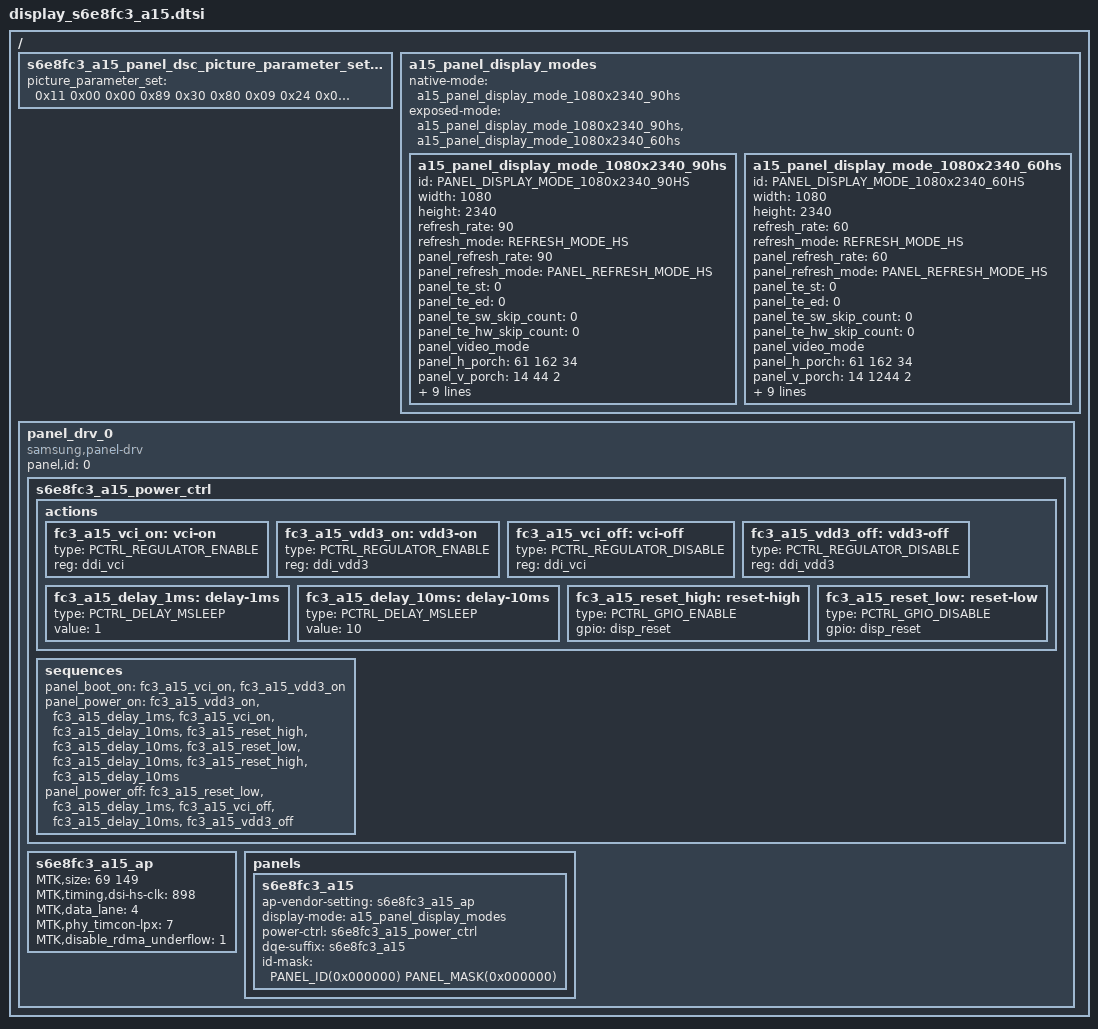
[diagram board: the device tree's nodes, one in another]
/*
 * Samsung Exynos SoC series Panel driver
 *
 * Copyright (c) 2020 Samsung Electronics Co., Ltd
 *
 * This program is free software; you can redistribute it and/or modify
 * it under the terms of the GNU General Public License version 2 as
 * published by the Free Software Foundation.
 */

#include <dt-bindings/display/panel-display.h>

/ {
	fragment@panel_display_mode {
		target-path = "/";
		__overlay__ {
			s6e8fc3_a15_panel_dsc_picture_parameter_set_default:
			s6e8fc3_a15_panel_dsc_picture_parameter_set_default {
					picture_parameter_set = /bits/ 8 <
						0x11 0x00 0x00 0x89 0x30 0x80 0x09 0x24
						0x04 0x38 0x00 0x2D 0x02 0x1C 0x02 0x1C
						0x02 0x00 0x02 0x0E 0x00 0x20 0x04 0x5A
						0x00 0x07 0x00 0x0C 0x02 0x2F 0x02 0x43
						0x18 0x00 0x10 0xF0 0x03 0x0C 0x20 0x00
						0x06 0x0B 0x0B 0x33 0x0E 0x1C 0x2A 0x38
						0x46 0x54 0x62 0x69 0x70 0x77 0x79 0x7B
						0x7D 0x7E 0x01 0x02 0x01 0x00 0x09 0x40
						0x09 0xBE 0x19 0xFC 0x19 0xFA 0x19 0xF8
						0x1A 0x38 0x1A 0x78 0x1A 0xB6 0x2A 0xF6
						0x2B 0x34 0x2B 0x74 0x3B 0x74 0x6B 0xF4
						0x00 0x00 0x00 0x00 0x00 0x00 0x00 0x00
						0x00 0x00 0x00 0x00 0x00 0x00 0x00 0x00
						0x00 0x00 0x00 0x00 0x00 0x00 0x00 0x00
						0x00 0x00 0x00 0x00 0x00 0x00 0x00 0x00
						0x00 0x00 0x00 0x00 0x00 0x00 0x00 0x00
					>;
			};

			a15_panel_display_modes:
			a15_panel_display_modes {
				native-mode = <&a15_panel_display_mode_1080x2340_90hs>;
				exposed-mode = <
					&a15_panel_display_mode_1080x2340_90hs
					&a15_panel_display_mode_1080x2340_60hs
				>;

				/* fhd */
				a15_panel_display_mode_1080x2340_90hs:
				a15_panel_display_mode_1080x2340_90hs {
					id = PANEL_DISPLAY_MODE_1080x2340_90HS;
					width = <1080>;
					height = <2340>;
					/* timing parameters */
					refresh_rate = <90>;			/* logical refresh rate */
					refresh_mode = <REFRESH_MODE_HS>;
					panel_refresh_rate = <90>;		/* panel internal refresh rate */
					panel_refresh_mode = <PANEL_REFRESH_MODE_HS>;
					panel_te_st = <0>;				/* te rising */
					panel_te_ed = <0>;				/* te falling */
					panel_te_sw_skip_count = <0>;	/* s/w te modulation */
					panel_te_hw_skip_count = <0>;	/* h/w te modulation */

					panel_video_mode;
					panel_h_porch = <61 162 34>;
					panel_v_porch = <14 44 2>;
					/* dsc parameters */
					dsc_en = <1>;			/* 0:Disable, 1:Enable */
					dsc_cnt = <1>;			/* used DSC count */
					dsc_slice_num = <2>;	/* count of dsc slice */
					dsc_slice_w = <540>;	/* width of dsc slice */
					dsc_slice_h = <117>;	/* height of dsc slice */
					dsc_picture_parameter_set = <&s6e8fc3_a15_panel_dsc_picture_parameter_set_default>;
					/* dsi parameters */
					cmd_lp_ref = <1761>;

					/*qos parameters */
					disp_qos_fps = <90>;
				};

				a15_panel_display_mode_1080x2340_60hs:
				a15_panel_display_mode_1080x2340_60hs {
					id = PANEL_DISPLAY_MODE_1080x2340_60HS;
					width = <1080>;
					height = <2340>;
					/* timing parameters */
					refresh_rate = <60>;			/* logical refresh rate */
					refresh_mode = <REFRESH_MODE_HS>;
					panel_refresh_rate = <60>;		/* panel internal refresh rate */
					panel_refresh_mode = <PANEL_REFRESH_MODE_HS>;
					panel_te_st = <0>;				/* te rising */
					panel_te_ed = <0>;				/* te falling */
					panel_te_sw_skip_count = <0>;	/* s/w te modulation */
					panel_te_hw_skip_count = <0>;	/* h/w te modulation */

					panel_video_mode;
					panel_h_porch = <61 162 34>;
					panel_v_porch = <14 1244 2>;

					/* dsc parameters */
					dsc_en = <1>;			/* 0:Disable, 1:Enable */
					dsc_cnt = <1>;			/* used DSC count */
					dsc_slice_num = <2>;	/* count of dsc slice */
					dsc_slice_w = <540>;	/* width of dsc slice */
					dsc_slice_h = <117>;	/* height of dsc slice */
					dsc_picture_parameter_set = <&s6e8fc3_a15_panel_dsc_picture_parameter_set_default>;

					/* dsi parameters */
					cmd_lp_ref = <7474>;

					/*qos parameters */
					disp_qos_fps = <90>;
				};
			};
		};
	};
};


/ {
	fragment@panel_drv {
		target-path = "/";
		__overlay__ {
			panel_drv_0: panel_drv_0 {
				status = "okay";
				compatible = "samsung,panel-drv";
				panel,id = <0>;

				s6e8fc3_a15_power_ctrl:
				s6e8fc3_a15_power_ctrl {
					actions {
						fc3_a15_vci_on: vci-on {
							type = <PCTRL_REGULATOR_ENABLE>;
							reg = <&ddi_vci>;
						};
						fc3_a15_vdd3_on: vdd3-on {
							type = <PCTRL_REGULATOR_ENABLE>;
							reg = <&ddi_vdd3>;
						};
						fc3_a15_vci_off: vci-off {
							type = <PCTRL_REGULATOR_DISABLE>;
							reg = <&ddi_vci>;
						};
						fc3_a15_vdd3_off: vdd3-off {
							type = <PCTRL_REGULATOR_DISABLE>;
							reg = <&ddi_vdd3>;
						};
						fc3_a15_delay_1ms: delay-1ms {
							type = <PCTRL_DELAY_MSLEEP>;
							value = <1>;
						};
						fc3_a15_delay_10ms: delay-10ms {
							type = <PCTRL_DELAY_MSLEEP>;
							value = <10>;
						};
						fc3_a15_reset_high: reset-high {
							type = <PCTRL_GPIO_ENABLE>;
							gpio = <&disp_reset>;
						};
						fc3_a15_reset_low: reset-low {
							type = <PCTRL_GPIO_DISABLE>;
							gpio = <&disp_reset>;
						};
					};
					sequences {
						panel_boot_on = <&fc3_a15_vci_on &fc3_a15_vdd3_on>;
						panel_power_on = <
								&fc3_a15_vdd3_on &fc3_a15_delay_1ms &fc3_a15_vci_on &fc3_a15_delay_10ms
								&fc3_a15_reset_high &fc3_a15_delay_10ms
								&fc3_a15_reset_low &fc3_a15_delay_10ms
								&fc3_a15_reset_high &fc3_a15_delay_10ms
						>;
						panel_power_off = <&fc3_a15_reset_low &fc3_a15_delay_1ms &fc3_a15_vci_off &fc3_a15_delay_10ms &fc3_a15_vdd3_off>;
					};
				};

				s6e8fc3_a15_ap:s6e8fc3_a15_ap {
					MTK,size = <69 149>; /* 68.6664 mm x 148.7772 mm */
					MTK,timing,dsi-hs-clk = <898>;
					MTK,data_lane = <4>;		/* number of using data lane */

					/* DSI phy timing */
					/* WARN: remove this if not needed. */
					MTK,phy_timcon-lpx = <7>;

					/* RDMA underflow -> DSI underrun */
					/* ALPS08461394 */
					MTK,disable_rdma_underflow = <1>;
				};

				panels {
					s6e8fc3_a15: s6e8fc3_a15 {
						ap-vendor-setting = <&s6e8fc3_a15_ap>;
						display-mode = <&a15_panel_display_modes>;
						power-ctrl = <&s6e8fc3_a15_power_ctrl>;
						dqe-suffix = "s6e8fc3_a15";
						id-mask = <
							PANEL_ID(0x000000) PANEL_MASK(0x000000)
						>;
					};
				};
			};
		};
	};
};

